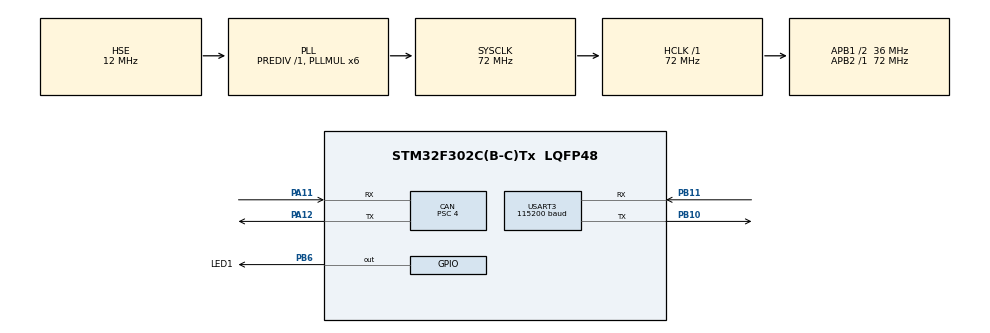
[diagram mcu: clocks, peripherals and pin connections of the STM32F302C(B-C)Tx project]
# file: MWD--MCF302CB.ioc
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CAN.BS1=CAN_BS1_6TQ
CAN.BS2=CAN_BS2_2TQ
CAN.CalculateBaudRate=1000000
CAN.CalculateTimeBit=999.99
CAN.CalculateTimeQuantum=111.11111111111111
CAN.Prescaler=4
CAN.RFLM=ENABLE
CAN.SJW=CAN_SJW_1TQ
Dma.Request0=USART3_TX
Dma.Request1=USART3_RX
Dma.USART3_RX.1.Direction=DMA_PERIPH_TO_MEMORY
Dma.USART3_RX.1.Instance=DMA1_Channel3
Dma.USART3_RX.1.MemDataAlignment=DMA_MDATAALIGN_BYTE
Dma.USART3_RX.1.MemInc=DMA_MINC_ENABLE
Dma.USART3_RX.1.Mode=DMA_CIRCULAR
Dma.USART3_RX.1.PeriphDataAlignment=DMA_PDATAALIGN_BYTE
Dma.USART3_RX.1.PeriphInc=DMA_PINC_DISABLE
Dma.USART3_RX.1.Priority=DMA_PRIORITY_HIGH
Dma.USART3_TX.0.Direction=DMA_MEMORY_TO_PERIPH
Dma.USART3_TX.0.Instance=DMA1_Channel2
Dma.USART3_TX.0.MemDataAlignment=DMA_MDATAALIGN_BYTE
Dma.USART3_TX.0.MemInc=DMA_MINC_ENABLE
Dma.USART3_TX.0.Mode=DMA_NORMAL
Dma.USART3_TX.0.PeriphDataAlignment=DMA_PDATAALIGN_BYTE
Dma.USART3_TX.0.PeriphInc=DMA_PINC_DISABLE
Dma.USART3_TX.0.Priority=DMA_PRIORITY_MEDIUM
Mcu.Family=STM32F3
Mcu.Name=STM32F302C(B-C)Tx
Mcu.Package=LQFP48
NVIC.DMA1_Channel2_IRQn=true\:1\:0\:true\:false\:true\:false\:true
NVIC.DMA1_Channel3_IRQn=true\:0\:0\:true\:false\:true\:false\:true
NVIC.PriorityGroup=NVIC_PRIORITYGROUP_4
NVIC.USB_HP_CAN_TX_IRQn=true\:1\:0\:true\:false\:true\:true\:true
NVIC.USB_LP_CAN_RX0_IRQn=true\:0\:0\:true\:false\:true\:true\:true
PA11.Mode=CAN_Activate
PA11.Signal=CAN_RX
PA12.Mode=CAN_Activate
PA12.Signal=CAN_TX
PA13.Mode=Serial_Wire
PA13.Signal=SYS_JTMS-SWDIO
PA14.Mode=Serial_Wire
PA14.Signal=SYS_JTCK-SWCLK
PB10.Mode=Asynchronous
PB10.Signal=USART3_TX
PB11.Mode=Asynchronous
PB11.Signal=USART3_RX
PB6.GPIO_Label=LED1
PB6.PinState=GPIO_PIN_SET
PB6.Signal=GPIO_Output
PF0-OSC_IN.Mode=HSE-External-Oscillator
PF0-OSC_IN.Signal=RCC_OSC_IN
PF1-OSC_OUT.Mode=HSE-External-Oscillator
PF1-OSC_OUT.Signal=RCC_OSC_OUT
ProjectManager.HeapSize=0x200
ProjectManager.StackSize=0x400
ProjectManager.TargetToolchain=MDK-ARM V5.27
RCC.AHBFreq_Value=72000000
RCC.APB1CLKDivider=RCC_HCLK_DIV2
RCC.APB1Freq_Value=36000000
RCC.APB1TimFreq_Value=72000000
RCC.APB2Freq_Value=72000000
RCC.APB2TimFreq_Value=72000000
RCC.CortexFreq_Value=72000000
RCC.HCLKFreq_Value=72000000
RCC.HSE_VALUE=12000000
RCC.HSI_VALUE=8000000
RCC.LSE_VALUE=32768
RCC.PLLMUL=RCC_PLL_MUL6
RCC.PLLSourceVirtual=RCC_PLLSOURCE_HSE
RCC.SYSCLKFreq_VALUE=72000000
RCC.SYSCLKSourceVirtual=RCC_SYSCLKSOURCE_PLLCLK
RCC.USBFreq_Value=72000000
USART3.BaudRate=115200
USART3.OverSampling=UART_OVERSAMPLING_8
USART3.VirtualMode-Asynchronous=VM_ASYNC
board=custom

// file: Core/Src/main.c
/* USER CODE BEGIN Header */
/**
  ******************************************************************************
  * @file           : main.c
  * @brief          : Main program body
  ******************************************************************************
  * @attention
  *
  * <h2><center>&copy; Copyright (c) 2021 STMicroelectronics.
  * All rights reserved.</center></h2>
  *
  * This software component is licensed by ST under BSD 3-Clause license,
  * the "License"; You may not use this file except in compliance with the
  * License. You may obtain a copy of the License at:
  *                        opensource.org/licenses/BSD-3-Clause
  *
	*
	*
  ******************************************************************************
  */
/* USER CODE END Header */
#include "main.h"
#include "can.h"
#include "dma.h"
#include "usart.h"
#include "gpio.h"

/* USER CODE BEGIN PV */
uint16_t encoderValue = 0;

static uint8_t motorId = 1;
static uint16_t ctlValue = 10 * 100;
static uint32_t txMailBox;
/* USER CODE END PV */

void SystemClock_Config(void);

int main(void)
{

  /* MCU Configuration--------------------------------------------------------*/

  /* Reset of all peripherals, Initializes the Flash interface and the Systick. */
  HAL_Init();

  /* Configure the system clock */
  SystemClock_Config();

  /* Initialize all configured peripherals */
  MX_GPIO_Init();
  MX_DMA_Init();
  MX_CAN_Init();
  MX_USART3_UART_Init();

  /* Infinite loop */
  while (1)
  {
		canTxHeader.StdId = DEVICE_STD_ID + motorId;
		canTxHeader.ExtId = 0x00;
		canTxHeader.RTR = CAN_RTR_DATA;
		canTxHeader.IDE = CAN_ID_STD;
		canTxHeader.DLC = 8;

		canTxData[0] = 0xA7;
		canTxData[1] = 0x00;
		canTxData[2] = 0x00;
		canTxData[3] = 0x00;
		canTxData[4] = *((uint8_t *)&ctlValue + 0);
		canTxData[5] = *((uint8_t *)&ctlValue + 1);
		canTxData[6] = 0x00;
		canTxData[7] = 0x00;

		/* send can command */
		HAL_CAN_AddTxMessage(&hcan, &canTxHeader, canTxData, &txMailBox);

		HAL_Delay(1000-1);
  }
}

/*********************************************************************************
* @brief	HAL_CAN_RxFifo0MsgPendingCallback, called in can interrupt
* @param	None
* @retval	None
*********************************************************************************/
void HAL_CAN_RxFifo0MsgPendingCallback(CAN_HandleTypeDef *hcan)
{
  /* Get RX message */
  if (HAL_CAN_GetRxMessage(hcan, CAN_RX_FIFO0, &canRxHeader, canRxData) != HAL_OK)
  {
    /* Reception Error */
    Error_Handler();
  }

  if ((canRxHeader.StdId == (DEVICE_STD_ID + motorId)) && (canRxHeader.DLC == 8))
  {
		/* get encoder value */
		encoderValue = (canRxData[7] << 8) + canRxData[6];

		LED1_TOGGLE();
  }
}

void SystemClock_Config(void)
{
  RCC_OscInitTypeDef RCC_OscInitStruct = {0};
  RCC_ClkInitTypeDef RCC_ClkInitStruct = {0};
  RCC_PeriphCLKInitTypeDef PeriphClkInit = {0};

  /** Initializes the RCC Oscillators according to the specified parameters
  * in the RCC_OscInitTypeDef structure.
  */
  RCC_OscInitStruct.OscillatorType = RCC_OSCILLATORTYPE_HSE;
  RCC_OscInitStruct.HSEState = RCC_HSE_ON;
  RCC_OscInitStruct.HSEPredivValue = RCC_HSE_PREDIV_DIV1;
  RCC_OscInitStruct.HSIState = RCC_HSI_ON;
  RCC_OscInitStruct.PLL.PLLState = RCC_PLL_ON;
  RCC_OscInitStruct.PLL.PLLSource = RCC_PLLSOURCE_HSE;
  RCC_OscInitStruct.PLL.PLLMUL = RCC_PLL_MUL6;
  if (HAL_RCC_OscConfig(&RCC_OscInitStruct) != HAL_OK)
  {
    Error_Handler();
  }
  /** Initializes the CPU, AHB and APB buses clocks
  */
  RCC_ClkInitStruct.ClockType = RCC_CLOCKTYPE_HCLK|RCC_CLOCKTYPE_SYSCLK
                              |RCC_CLOCKTYPE_PCLK1|RCC_CLOCKTYPE_PCLK2;
  RCC_ClkInitStruct.SYSCLKSource = RCC_SYSCLKSOURCE_PLLCLK;
  RCC_ClkInitStruct.AHBCLKDivider = RCC_SYSCLK_DIV1;
  RCC_ClkInitStruct.APB1CLKDivider = RCC_HCLK_DIV2;
  RCC_ClkInitStruct.APB2CLKDivider = RCC_HCLK_DIV1;

  if (HAL_RCC_ClockConfig(&RCC_ClkInitStruct, FLASH_LATENCY_2) != HAL_OK)
  {
    Error_Handler();
  }
  PeriphClkInit.PeriphClockSelection = RCC_PERIPHCLK_USART3;
  PeriphClkInit.Usart3ClockSelection = RCC_USART3CLKSOURCE_PCLK1;
  if (HAL_RCCEx_PeriphCLKConfig(&PeriphClkInit) != HAL_OK)
  {
    Error_Handler();
  }
}

void Error_Handler(void)
{
  __disable_irq();
  while (1)
  {
  }
}

/************************ (C) COPYRIGHT STMicroelectronics *****END OF FILE****/
